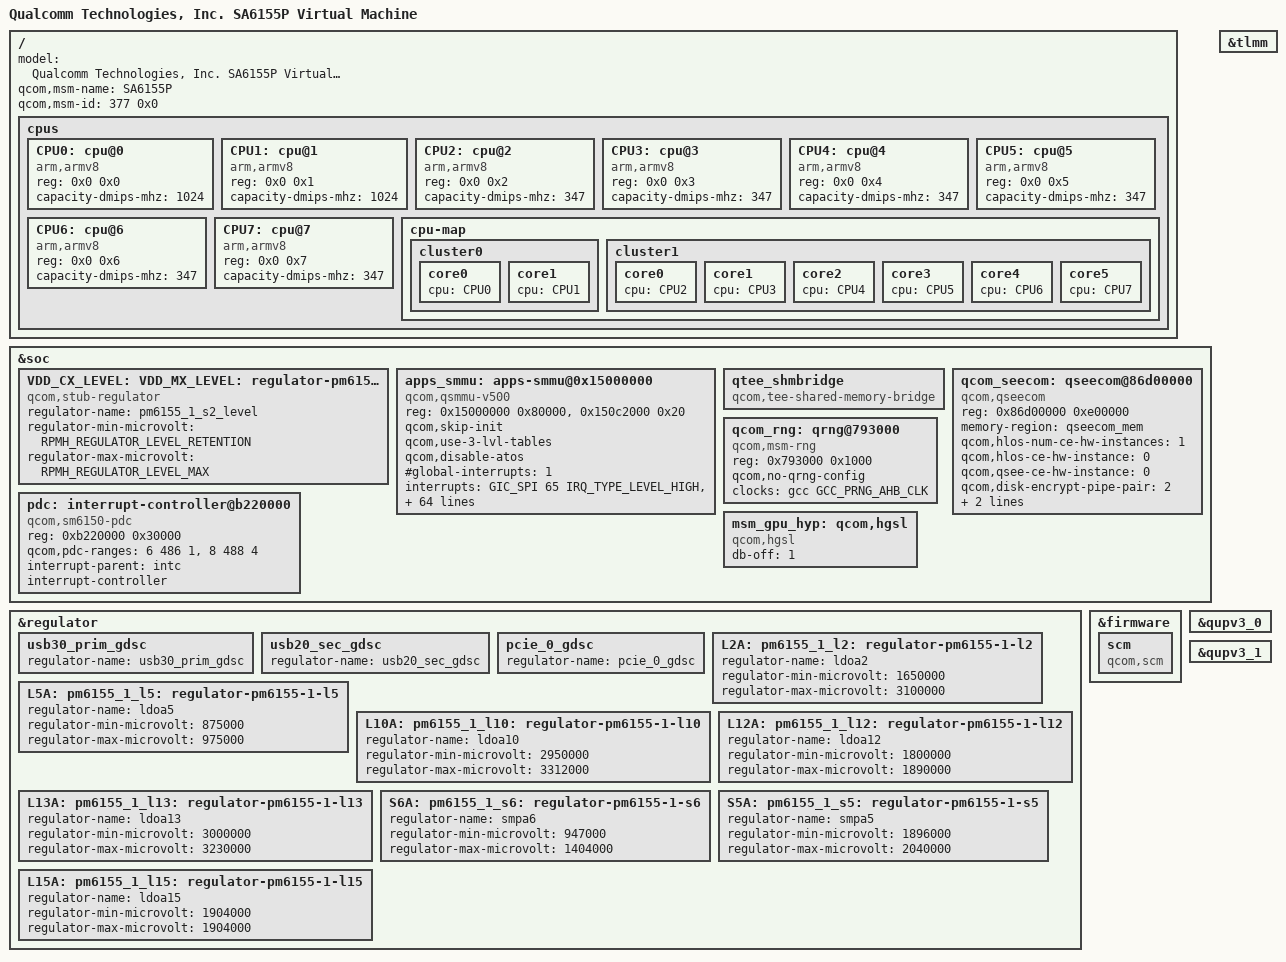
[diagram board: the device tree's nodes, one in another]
#include <dt-bindings/clock/qcom,gcc-sm6150.h>
#include <dt-bindings/clock/qcom,scc-sm6150.h>
#include <dt-bindings/regulator/qcom,rpmh-regulator.h>
#include <dt-bindings/regulator/qcom,rpmh-regulator-levels.h>
#include <dt-bindings/interrupt-controller/arm-gic.h>
#include <dt-bindings/gpio/gpio.h>
#include "quin-vm-common.dtsi"

/ {
	model = "Qualcomm Technologies, Inc. SA6155P Virtual Machine";
	qcom,msm-name = "SA6155P";
	qcom,msm-id = <377 0x0>;

	cpus {
		#address-cells = <2>;
		#size-cells = <0>;

		CPU0: cpu@0 {
			device_type = "cpu";
			compatible = "arm,armv8";
			reg = <0x0 0x0>;
			capacity-dmips-mhz = <1024>;
		};

		CPU1: cpu@1 {
			device_type = "cpu";
			compatible = "arm,armv8";
			reg = <0x0 0x1>;
			capacity-dmips-mhz = <1024>;
		};

		CPU2: cpu@2 {
			device_type = "cpu";
			compatible = "arm,armv8";
			reg = <0x0 0x2>;
			capacity-dmips-mhz = <347>;
		};

		CPU3: cpu@3 {
			device_type = "cpu";
			compatible = "arm,armv8";
			reg = <0x0 0x3>;
			capacity-dmips-mhz = <347>;
		};

		CPU4: cpu@4 {
			device_type = "cpu";
			compatible = "arm,armv8";
			reg = <0x0 0x4>;
			capacity-dmips-mhz = <347>;
		};

		CPU5: cpu@5 {
			device_type = "cpu";
			compatible = "arm,armv8";
			reg = <0x0 0x5>;
			capacity-dmips-mhz = <347>;
		};

		CPU6: cpu@6 {
			device_type = "cpu";
			compatible = "arm,armv8";
			reg = <0x0 0x6>;
			capacity-dmips-mhz = <347>;
		};

		CPU7: cpu@7 {
			device_type = "cpu";
			compatible = "arm,armv8";
			reg = <0x0 0x7>;
			capacity-dmips-mhz = <347>;
		};

		cpu-map {
			cluster0 {
				core0 {
					cpu = <&CPU0>;
				};

				core1 {
					cpu = <&CPU1>;
				};
			};

			cluster1 {
				core0 {
					cpu = <&CPU2>;
				};

				core1 {
					cpu = <&CPU3>;
				};

				core2 {
					cpu = <&CPU4>;
				};

				core3 {
					cpu = <&CPU5>;
				};

				core4 {
					cpu = <&CPU6>;
				};

				core5 {
					cpu = <&CPU7>;
				};
			};
		};
	};
};


&soc {
	VDD_CX_LEVEL: VDD_MX_LEVEL: S2A_LEVEL:
		pm6155_1_s2_level: regulator-pm6155-1-s2-level {
		compatible = "qcom,stub-regulator";
		regulator-name = "pm6155_1_s2_level";
		regulator-min-microvolt
			= <RPMH_REGULATOR_LEVEL_RETENTION>;
		regulator-max-microvolt
			= <RPMH_REGULATOR_LEVEL_MAX>;
	};

	apps_smmu: apps-smmu@0x15000000 {
		compatible = "qcom,qsmmu-v500";
		reg = <0x15000000 0x80000>,
			<0x150c2000 0x20>;
		reg-names = "base", "tcu-base";
		#iommu-cells = <2>;
		qcom,skip-init;
		qcom,use-3-lvl-tables;
		qcom,disable-atos;
		#global-interrupts = <1>;
		#size-cells = <1>;
		#address-cells = <1>;
		ranges;
		interrupts =	<GIC_SPI 65 IRQ_TYPE_LEVEL_HIGH>,
				<GIC_SPI 94 IRQ_TYPE_LEVEL_HIGH>,
				<GIC_SPI 95 IRQ_TYPE_LEVEL_HIGH>,
				<GIC_SPI 96 IRQ_TYPE_LEVEL_HIGH>,
				<GIC_SPI 97 IRQ_TYPE_LEVEL_HIGH>,
				<GIC_SPI 98 IRQ_TYPE_LEVEL_HIGH>,
				<GIC_SPI 99 IRQ_TYPE_LEVEL_HIGH>,
				<GIC_SPI 100 IRQ_TYPE_LEVEL_HIGH>,
				<GIC_SPI 101 IRQ_TYPE_LEVEL_HIGH>,
				<GIC_SPI 102 IRQ_TYPE_LEVEL_HIGH>,
				<GIC_SPI 103 IRQ_TYPE_LEVEL_HIGH>,
				<GIC_SPI 104 IRQ_TYPE_LEVEL_HIGH>,
				<GIC_SPI 105 IRQ_TYPE_LEVEL_HIGH>,
				<GIC_SPI 106 IRQ_TYPE_LEVEL_HIGH>,
				<GIC_SPI 107 IRQ_TYPE_LEVEL_HIGH>,
				<GIC_SPI 108 IRQ_TYPE_LEVEL_HIGH>,
				<GIC_SPI 109 IRQ_TYPE_LEVEL_HIGH>,
				<GIC_SPI 110 IRQ_TYPE_LEVEL_HIGH>,
				<GIC_SPI 111 IRQ_TYPE_LEVEL_HIGH>,
				<GIC_SPI 112 IRQ_TYPE_LEVEL_HIGH>,
				<GIC_SPI 113 IRQ_TYPE_LEVEL_HIGH>,
				<GIC_SPI 114 IRQ_TYPE_LEVEL_HIGH>,
				<GIC_SPI 115 IRQ_TYPE_LEVEL_HIGH>,
				<GIC_SPI 116 IRQ_TYPE_LEVEL_HIGH>,
				<GIC_SPI 117 IRQ_TYPE_LEVEL_HIGH>,
				<GIC_SPI 118 IRQ_TYPE_LEVEL_HIGH>,
				<GIC_SPI 181 IRQ_TYPE_LEVEL_HIGH>,
				<GIC_SPI 182 IRQ_TYPE_LEVEL_HIGH>,
				<GIC_SPI 183 IRQ_TYPE_LEVEL_HIGH>,
				<GIC_SPI 184 IRQ_TYPE_LEVEL_HIGH>,
				<GIC_SPI 185 IRQ_TYPE_LEVEL_HIGH>,
				<GIC_SPI 186 IRQ_TYPE_LEVEL_HIGH>,
				<GIC_SPI 187 IRQ_TYPE_LEVEL_HIGH>,
				<GIC_SPI 188 IRQ_TYPE_LEVEL_HIGH>,
				<GIC_SPI 189 IRQ_TYPE_LEVEL_HIGH>,
				<GIC_SPI 190 IRQ_TYPE_LEVEL_HIGH>,
				<GIC_SPI 191 IRQ_TYPE_LEVEL_HIGH>,
				<GIC_SPI 192 IRQ_TYPE_LEVEL_HIGH>,
				<GIC_SPI 315 IRQ_TYPE_LEVEL_HIGH>,
				<GIC_SPI 316 IRQ_TYPE_LEVEL_HIGH>,
				<GIC_SPI 317 IRQ_TYPE_LEVEL_HIGH>,
				<GIC_SPI 318 IRQ_TYPE_LEVEL_HIGH>,
				<GIC_SPI 319 IRQ_TYPE_LEVEL_HIGH>,
				<GIC_SPI 320 IRQ_TYPE_LEVEL_HIGH>,
				<GIC_SPI 321 IRQ_TYPE_LEVEL_HIGH>,
				<GIC_SPI 322 IRQ_TYPE_LEVEL_HIGH>,
				<GIC_SPI 323 IRQ_TYPE_LEVEL_HIGH>,
				<GIC_SPI 324 IRQ_TYPE_LEVEL_HIGH>,
				<GIC_SPI 325 IRQ_TYPE_LEVEL_HIGH>,
				<GIC_SPI 326 IRQ_TYPE_LEVEL_HIGH>,
				<GIC_SPI 327 IRQ_TYPE_LEVEL_HIGH>,
				<GIC_SPI 328 IRQ_TYPE_LEVEL_HIGH>,
				<GIC_SPI 329 IRQ_TYPE_LEVEL_HIGH>,
				<GIC_SPI 330 IRQ_TYPE_LEVEL_HIGH>,
				<GIC_SPI 331 IRQ_TYPE_LEVEL_HIGH>,
				<GIC_SPI 332 IRQ_TYPE_LEVEL_HIGH>,
				<GIC_SPI 333 IRQ_TYPE_LEVEL_HIGH>,
				<GIC_SPI 334 IRQ_TYPE_LEVEL_HIGH>,
				<GIC_SPI 335 IRQ_TYPE_LEVEL_HIGH>,
				<GIC_SPI 336 IRQ_TYPE_LEVEL_HIGH>,
				<GIC_SPI 337 IRQ_TYPE_LEVEL_HIGH>,
				<GIC_SPI 338 IRQ_TYPE_LEVEL_HIGH>,
				<GIC_SPI 339 IRQ_TYPE_LEVEL_HIGH>,
				<GIC_SPI 340 IRQ_TYPE_LEVEL_HIGH>,
				<GIC_SPI 341 IRQ_TYPE_LEVEL_HIGH>;
	};

	qtee_shmbridge {
		compatible = "qcom,tee-shared-memory-bridge";
	};

	qcom_seecom: qseecom@86d00000 {
		compatible = "qcom,qseecom";
		reg = <0x86d00000 0xe00000>;
		reg-names = "secapp-region";
		memory-region = <&qseecom_mem>;
		qcom,hlos-num-ce-hw-instances = <1>;
		qcom,hlos-ce-hw-instance = <0>;
		qcom,qsee-ce-hw-instance = <0>;
		qcom,disk-encrypt-pipe-pair = <2>;
		qcom,no-clock-support;
		qcom,qsee-reentrancy-support = <2>;
	};

	qcom_rng: qrng@793000 {
		compatible = "qcom,msm-rng";
		reg = <0x793000 0x1000>;
		qcom,no-qrng-config;
		clocks = <&gcc GCC_PRNG_AHB_CLK>;
		clock-names = "km_clk_src";
	};

	pdc: interrupt-controller@b220000 {
		compatible = "qcom,sm6150-pdc";
		reg = <0xb220000 0x30000>;
		qcom,pdc-ranges = <6 486 1>, <8 488 4>;
		#interrupt-cells = <2>;
		interrupt-parent = <&intc>;
		interrupt-controller;
	};

	msm_gpu_hyp: qcom,hgsl {
		compatible = "qcom,hgsl";

		/* 6155 have no Doorbell, only keep ifence */
		db-off = <1>;
	};
};

&regulator {
	usb30_prim_gdsc: usb30_prim_gdsc {
		regulator-name = "usb30_prim_gdsc";
	};

	usb20_sec_gdsc: usb20_sec_gdsc {
		regulator-name = "usb20_sec_gdsc";
	};

	pcie_0_gdsc: pcie_0_gdsc {
		regulator-name = "pcie_0_gdsc";
	};

	L2A: pm6155_1_l2: regulator-pm6155-1-l2 {
		regulator-name = "ldoa2";
		regulator-min-microvolt = <1650000>;
		regulator-max-microvolt = <3100000>;
	};

	L5A: pm6155_1_l5: regulator-pm6155-1-l5 {
		regulator-name = "ldoa5";
		regulator-min-microvolt = <875000>;
		regulator-max-microvolt = <975000>;
	};

	L10A: pm6155_1_l10: regulator-pm6155-1-l10 {
		regulator-name = "ldoa10";
		regulator-min-microvolt = <2950000>;
		regulator-max-microvolt = <3312000>;
	};

	L12A: pm6155_1_l12: regulator-pm6155-1-l12 {
		regulator-name = "ldoa12";
		regulator-min-microvolt = <1800000>;
		regulator-max-microvolt = <1890000>;
	};

	L13A: pm6155_1_l13: regulator-pm6155-1-l13 {
		regulator-name = "ldoa13";
		regulator-min-microvolt = <3000000>;
		regulator-max-microvolt = <3230000>;
	};

	S6A: pm6155_1_s6: regulator-pm6155-1-s6 {
		regulator-name = "smpa6";
		regulator-min-microvolt = <947000>;
		regulator-max-microvolt = <1404000>;
	};

	S5A: pm6155_1_s5: regulator-pm6155-1-s5 {
		regulator-name = "smpa5";
		regulator-min-microvolt = <1896000>;
		regulator-max-microvolt = <2040000>;
	};

	L15A: pm6155_1_l15: regulator-pm6155-1-l15 {
		regulator-name = "ldoa15";
		regulator-min-microvolt = <1904000>;
		regulator-max-microvolt = <1904000>;
	};
};

&firmware {
	scm {
		compatible = "qcom,scm";
	};
};

#include "sm6150-pinctrl.dtsi"
#include "sa6155p-vm-usb.dtsi"
#include "sa6155p-vm-pcie.dtsi"
#include "sm6150-qupv3.dtsi"
#include "sa8155-vm-audio.dtsi"

&tlmm {
	/delete-property/ wakeup-parent;
};

&qupv3_0 {
	/delete-property/ qcom,msm-bus,num-paths;
	/delete-property/ qcom,msm-bus,vectors-bus-ids;
};

&qupv3_1 {
	/delete-property/ qcom,msm-bus,num-paths;
	/delete-property/ qcom,msm-bus,vectors-bus-ids;
};

